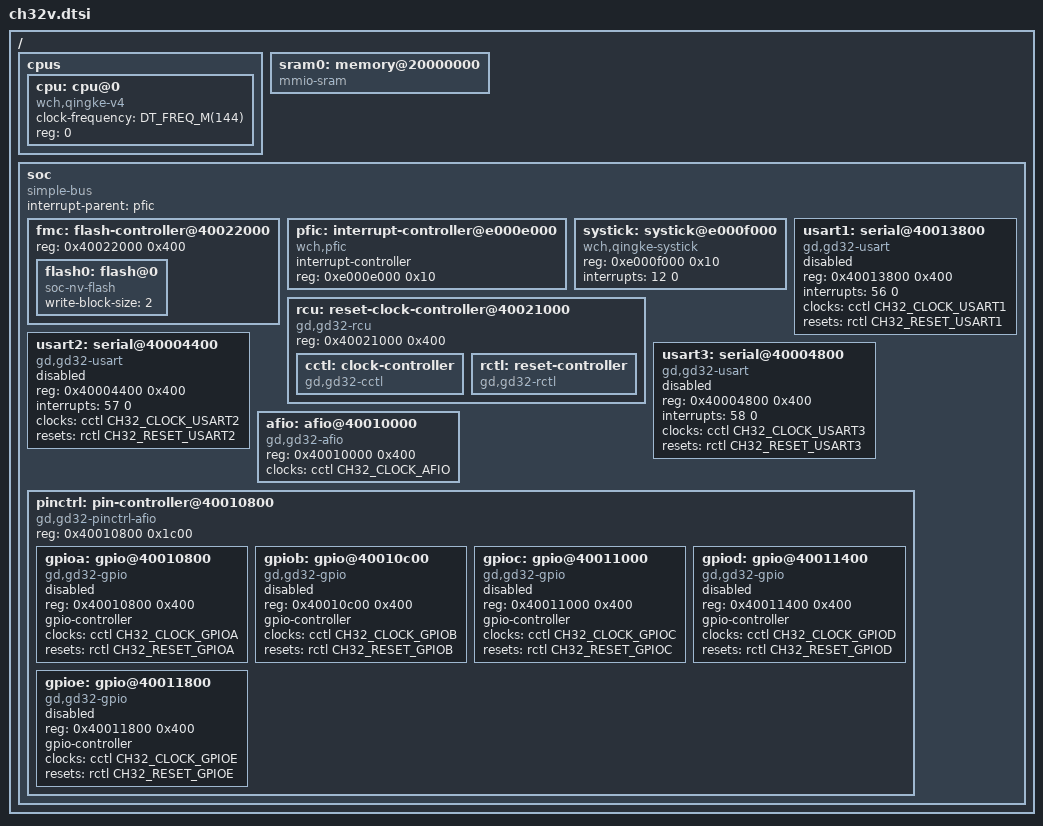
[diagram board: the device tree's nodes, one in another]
/*
 * Copyright (c) 2022 TOKITA Hiroshi <tokita.hiroshi@gmail.com>
 *
 * SPDX-License-Identifier: Apache-2.0
 */

#include <freq.h>
#include <zephyr/dt-bindings/gpio/gpio.h>
#include <zephyr/dt-bindings/clock/ch32v30x-clocks.h>
#include <zephyr/dt-bindings/reset/ch32v30x.h>

/ {
	#address-cells = <1>;
	#size-cells = <1>;

	cpus {
		#address-cells = <1>;
		#size-cells = <0>;

		cpu: cpu@0 {
			clock-frequency = <DT_FREQ_M(144)>;
			compatible = "wch,qingke-v4";
			reg = <0>;
		};
	};

	sram0: memory@20000000 {
		compatible = "mmio-sram";
	};

	soc {
		#address-cells = <1>;
		#size-cells = <1>;
		compatible = "simple-bus";
		interrupt-parent = <&pfic>;
		ranges;

		fmc: flash-controller@40022000 {
			/*compatible = "gd,gd32-flash-controller";*/
			reg = <0x40022000 0x400>;
			#address-cells = <1>;
			#size-cells = <1>;

			flash0: flash@0 {
				compatible = "soc-nv-flash";
				write-block-size = <2>;
			};
		};

		pfic: interrupt-controller@e000e000 {
			compatible = "wch,pfic";
			#address-cells = <0>;
			#interrupt-cells = <2>;
			interrupt-controller;
			reg = <0xe000e000 0x10>;
		};

		systick: systick@e000f000 {
			compatible = "wch,qingke-systick";
			reg = <0xe000f000 0x10>;
			interrupts = <12 0>;
		};

		rcu: reset-clock-controller@40021000 {
			compatible = "gd,gd32-rcu";
			reg = <0x40021000 0x400>;
			status = "okay";

			cctl: clock-controller {
				compatible = "gd,gd32-cctl";
				#clock-cells = <1>;
				status = "okay";
			};

			rctl: reset-controller {
				compatible = "gd,gd32-rctl";
				#reset-cells = <1>;
				status = "okay";
			};
		};

		usart1: serial@40013800 {
			compatible = "gd,gd32-usart";
			reg = <0x40013800 0x400>;
			interrupts = <56 0>;
			clocks = <&cctl CH32_CLOCK_USART1>;
			resets = <&rctl CH32_RESET_USART1>;
			status = "disabled";
		};

		usart2: serial@40004400 {
			compatible = "gd,gd32-usart";
			reg = <0x40004400 0x400>;
			interrupts = <57 0>;
			clocks = <&cctl CH32_CLOCK_USART2>;
			resets = <&rctl CH32_RESET_USART2>;
			status = "disabled";
		};

		usart3: serial@40004800 {
			compatible = "gd,gd32-usart";
			reg = <0x40004800 0x400>;
			interrupts = <58 0>;
			clocks = <&cctl CH32_CLOCK_USART3>;
			resets = <&rctl CH32_RESET_USART3>;
			status = "disabled";
		};

		afio: afio@40010000 {
			compatible = "gd,gd32-afio";
			reg = <0x40010000 0x400>;
			clocks = <&cctl CH32_CLOCK_AFIO>;
			status = "okay";
		};

		pinctrl: pin-controller@40010800 {
			compatible = "gd,gd32-pinctrl-afio";
			reg = <0x40010800 0x1c00>;
			#address-cells = <1>;
			#size-cells = <1>;
			status = "okay";

			gpioa: gpio@40010800 {
				compatible = "gd,gd32-gpio";
				reg = <0x40010800 0x400>;
				gpio-controller;
				#gpio-cells = <2>;
				clocks = <&cctl CH32_CLOCK_GPIOA>;
				resets = <&rctl CH32_RESET_GPIOA>;
				status = "disabled";
			};

			gpiob: gpio@40010c00 {
				compatible = "gd,gd32-gpio";
				reg = <0x40010c00 0x400>;
				gpio-controller;
				#gpio-cells = <2>;
				clocks = <&cctl CH32_CLOCK_GPIOB>;
				resets = <&rctl CH32_RESET_GPIOB>;
				status = "disabled";
			};

			gpioc: gpio@40011000 {
				compatible = "gd,gd32-gpio";
				reg = <0x40011000 0x400>;
				gpio-controller;
				#gpio-cells = <2>;
				clocks = <&cctl CH32_CLOCK_GPIOC>;
				resets = <&rctl CH32_RESET_GPIOC>;
				status = "disabled";
			};

			gpiod: gpio@40011400 {
				compatible = "gd,gd32-gpio";
				reg = <0x40011400 0x400>;
				gpio-controller;
				#gpio-cells = <2>;
				clocks = <&cctl CH32_CLOCK_GPIOD>;
				resets = <&rctl CH32_RESET_GPIOD>;
				status = "disabled";
			};

			gpioe: gpio@40011800 {
				compatible = "gd,gd32-gpio";
				reg = <0x40011800 0x400>;
				gpio-controller;
				#gpio-cells = <2>;
				clocks = <&cctl CH32_CLOCK_GPIOE>;
				resets = <&rctl CH32_RESET_GPIOE>;
				status = "disabled";
			};
		};
	};
};
